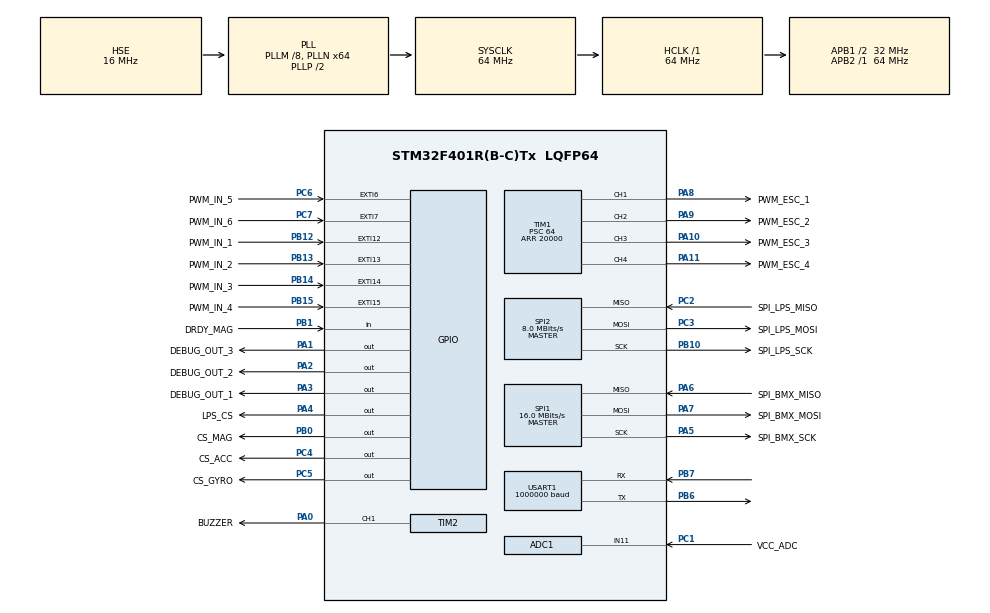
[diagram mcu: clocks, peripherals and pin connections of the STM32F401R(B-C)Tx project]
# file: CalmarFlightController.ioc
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Mcu.Family=STM32F4
PC3.Mode=Full_Duplex_Master
PA6.Mode=Full_Duplex_Master
SH.S_TIM1_CH4.0=TIM1_CH4,PWM Generation4 CH4
RCC.CortexFreq_Value=64000000
SPI1.VirtualType=VM_MASTER
SPI2.VirtualType=VM_MASTER
PB10.Mode=Full_Duplex_Master
ADC1.ContinuousConvMode=DISABLE
USART1.BaudRate=1000000
PB14.GPIO_Label=PWM_IN_3
PC6.GPIO_Label=PWM_IN_5
PA6.GPIO_Label=SPI_BMX_MISO
PB0.GPIO_Label=CS_MAG
TIM1.Pulse-PWM\ Generation1\ CH1=1000
PB13.GPIO_Label=PWM_IN_2
PB13.Signal=GPXTI13
PB15.Signal=GPXTI15
RCC.SYSCLKSource=RCC_SYSCLKSOURCE_PLLCLK
ProjectManager.StackSize=0x400
TIM1.OC1Preload_PWM=ENABLE
TIM1.Prescaler=64
SPI1.CLKPolarity=SPI_POLARITY_LOW
PH0\ -\ OSC_IN.Signal=RCC_OSC_IN
TIM1.Channel-PWM\ Generation4\ CH4=TIM_CHANNEL_4
SPI1.Direction=SPI_DIRECTION_2LINES
RCC.HCLKFreq_Value=64000000
RCC.APB2TimFreq_Value=64000000
PB6.Signal=USART1_TX
Dma.ADC1.0.Direction=DMA_PERIPH_TO_MEMORY
ADC1.Channel-2\#ChannelRegularConversion=ADC_CHANNEL_11
PC7.Signal=GPXTI7
ADC1.InjNumberOfConversion=0
PB6.Mode=Asynchronous
SPI1.CalculateBaudRate=16.0 MBits/s
PC3.Signal=SPI2_MOSI
NVIC.DMA2_Stream0_IRQn=true\:5\:0\:false\:false\:true\:true\:false\:true
FREERTOS.configMINIMAL_STACK_SIZE=128
Dma.ADC1.0.MemDataAlignment=DMA_MDATAALIGN_WORD
RCC.AHBFreq_Value=64000000
SPI2.BaudRatePrescaler=SPI_BAUDRATEPRESCALER_4
NVIC.EXTI15_10_IRQn=true\:5\:0\:false\:false\:true\:true\:true\:true
RCC.HSE_VALUE=16000000
PB12.GPIO_Label=PWM_IN_1
ADC1.Rank-2\#ChannelRegularConversion=1
PC4.GPIO_Label=CS_ACC
TIM1.Channel-PWM\ Generation1\ CH1=TIM_CHANNEL_1
TIM1.OC2Preload_PWM=ENABLE
PB1.GPIO_Label=DRDY_MAG
Dma.ADC1.0.PeriphInc=DMA_PINC_DISABLE
NVIC.TIM2_IRQn=true\:5\:0\:false\:false\:true\:true\:true\:true
PA10.GPIO_Label=PWM_ESC_3
SPI2.CalculateBaudRate=8.0 MBits/s
PB7.Signal=USART1_RX
PA8.Signal=S_TIM1_CH1
TIM2.Channel-PWM\ Generation1\ CH1=TIM_CHANNEL_1
VP_FREERTOS_VS_CMSIS_V1.Mode=CMSIS_V1
VP_TIM1_VS_ClockSourceINT.Mode=Internal
PC7.GPIO_ModeDefaultEXTI=GPIO_MODE_IT_RISING_FALLING
Mcu.Package=LQFP64
TIM2.Prescaler=64
PB1.Signal=GPIO_Input
PA6.Signal=SPI1_MISO
NVIC.TimeBase=TIM3_IRQn
SPI2.Mode=SPI_MODE_MASTER
TIM1.Pulse-PWM\ Generation2\ CH2=1000
PA2.GPIO_Label=DEBUG_OUT_2
NVIC.TimeBaseIP=TIM3
PA10.Signal=S_TIM1_CH3
RCC.APB1TimFreq_Value=64000000
Dma.ADC1.0.FIFOMode=DMA_FIFOMODE_DISABLE
SPI2.Direction=SPI_DIRECTION_2LINES
PC5.Signal=GPIO_Output
TIM1.Period=20000
Dma.Request0=ADC1
SPI1.BaudRatePrescaler=SPI_BAUDRATEPRESCALER_4
PA4.GPIO_Label=LPS_CS
PC2.GPIO_Label=SPI_LPS_MISO
ADC1.EOCSelection=ADC_EOC_SEQ_CONV
PA3.Signal=GPIO_Output
PA5.Mode=Full_Duplex_Master
PB14.GPIO_ModeDefaultEXTI=GPIO_MODE_IT_RISING_FALLING
RCC.PLLSourceVirtual=RCC_PLLSOURCE_HSE
Dma.ADC1.0.Instance=DMA2_Stream0
FREERTOS.Tasks01=defaultTask,-3,128,StartDefaultTask,Default,NULL,Dynamic,NULL,NULL
PA7.Mode=Full_Duplex_Master
PA9.GPIO_Label=PWM_ESC_2
FREERTOS.INCLUDE_vTaskDelayUntil=1
TIM1.OC3Preload_PWM=ENABLE
PH1\ -\ OSC_OUT.Mode=HSE-External-Oscillator
PC2.Signal=SPI2_MISO
PC4.Signal=GPIO_Output
PC6.Signal=GPXTI6
PA11.GPIO_Label=PWM_ESC_4
PC2.Mode=Full_Duplex_Master
SPI1.CLKPhase=SPI_PHASE_1EDGE
TIM1.OC4Preload_PWM=ENABLE
RCC.APB1CLKDivider=RCC_HCLK_DIV2
PB13.GPIO_ModeDefaultEXTI=GPIO_MODE_IT_RISING_FALLING
ADC1.SamplingTime-2\#ChannelRegularConversion=ADC_SAMPLETIME_3CYCLES
PA0-WKUP.GPIO_Label=BUZZER
PA0-WKUP.Signal=S_TIM2_CH1_ETR
TIM1.ClockDivision=TIM_CLOCKDIVISION_DIV1
TIM2.Pulse-PWM\ Generation1\ CH1=1000
TIM1.Pulse-PWM\ Generation3\ CH3=1000
TIM1.AutoReloadPreload=TIM_AUTORELOAD_PRELOAD_ENABLE
Dma.ADC1.0.PeriphDataAlignment=DMA_PDATAALIGN_WORD
PH0\ -\ OSC_IN.Mode=HSE-External-Oscillator
VP_SYS_VS_tim3.Mode=TIM3
PA8.GPIO_Label=PWM_ESC_1
SH.S_TIM1_CH1.0=TIM1_CH1,PWM Generation1 CH1
PC6.GPIO_ModeDefaultEXTI=GPIO_MODE_IT_RISING_FALLING
ProjectManager.TargetToolchain=STM32CubeIDE
PB10.GPIO_Label=SPI_LPS_SCK
Dma.ADC1.0.Mode=DMA_CIRCULAR
Dma.ADC1.0.Priority=DMA_PRIORITY_LOW
PA9.Signal=S_TIM1_CH2
TIM1.Channel-PWM\ Generation2\ CH2=TIM_CHANNEL_2
RCC.LSE_VALUE=32768
PA1.Signal=GPIO_Output
PB10.Signal=SPI2_SCK
PB14.Signal=GPXTI14
PA5.Signal=SPI1_SCK
PB15.GPIO_ModeDefaultEXTI=GPIO_MODE_IT_RISING_FALLING
PH1\ -\ OSC_OUT.Signal=RCC_OSC_OUT
board=custom
RCC.VCOOutputFreq_Value=128000000
NVIC.TIM3_IRQn=true\:0\:0\:false\:false\:true\:false\:false\:true
FREERTOS.INCLUDE_eTaskGetState=1
TIM1.TIM_MasterOutputTrigger=TIM_TRGO_UPDATE
RCC.APB2Freq_Value=64000000
SH.ADCx_IN11.0=ADC1_IN11,IN11
PB15.GPIO_Label=PWM_IN_4
SH.S_TIM1_CH2.0=TIM1_CH2,PWM Generation2 CH2
VP_TIM2_VS_ClockSourceINT.Mode=Internal
SPI1.Mode=SPI_MODE_MASTER
PA1.GPIO_Label=DEBUG_OUT_3
PC1.GPIO_Label=VCC_ADC
ADC1.DMAContinuousRequests=ENABLE
TIM2.Period=2000
ADC1.NbrOfConversion=1
Mcu.Name=STM32F401R(B-C)Tx
PA2.Signal=GPIO_Output
PC7.GPIO_Label=PWM_IN_6
RCC.48MHZClocksFreq_Value=32000000
PA4.Signal=GPIO_Output
RCC.SYSCLKFreq_VALUE=64000000
PA7.GPIO_Label=SPI_BMX_MOSI
ADC1.master=1
PA5.GPIO_Label=SPI_BMX_SCK
PC5.GPIO_Label=CS_GYRO
USART1.VirtualMode=VM_ASYNC
PA11.Signal=S_TIM1_CH4
PB7.Mode=Asynchronous
SH.S_TIM2_CH1_ETR.0=TIM2_CH1,PWM Generation1 CH1
NVIC.EXTI9_5_IRQn=true\:5\:0\:false\:false\:true\:true\:true\:true
Dma.ADC1.0.MemInc=DMA_MINC_ENABLE
ProjectManager.HeapSize=0x200
SH.S_TIM1_CH3.0=TIM1_CH3,PWM Generation3 CH3
TIM1.Pulse-PWM\ Generation4\ CH4=1000
PB12.GPIO_ModeDefaultEXTI=GPIO_MODE_IT_RISING_FALLING
RCC.HSI_VALUE=16000000
NVIC.PriorityGroup=NVIC_PRIORITYGROUP_4
ADC1.NbrOfConversionFlag=1
RCC.PLLM=8
RCC.PLLN=64
TIM2.AutoReloadPreload=TIM_AUTORELOAD_PRELOAD_ENABLE
PC3.GPIO_Label=SPI_LPS_MOSI
TIM1.Channel-PWM\ Generation3\ CH3=TIM_CHANNEL_3
RCC.APB1Freq_Value=32000000
PB0.Signal=GPIO_Output
ADC1.ClockPrescaler=ADC_CLOCK_SYNC_PCLK_DIV2
PC1.Signal=ADCx_IN11
PB12.Signal=GPXTI12
PA3.GPIO_Label=DEBUG_OUT_1
PA7.Signal=SPI1_MOSI

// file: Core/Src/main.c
/* USER CODE BEGIN Header */
/**
  ******************************************************************************
  * @file           : main.c
  * @brief          : Main program body
  ******************************************************************************
  * @attention
  *
  * <h2><center>&copy; Copyright (c) 2020 STMicroelectronics.
  * All rights reserved.</center></h2>
  *
  * This software component is licensed by ST under BSD 3-Clause license,
  * the "License"; You may not use this file except in compliance with the
  * License. You may obtain a copy of the License at:
  *                        opensource.org/licenses/BSD-3-Clause
  *
  ******************************************************************************
  */
/* USER CODE END Header */
#include "main.h"
#include "cmsis_os.h"

/* USER CODE BEGIN Includes */
#include "app/deviceManager/deviceManager.h"
/* USER CODE END Includes */

ADC_HandleTypeDef hadc1;
DMA_HandleTypeDef hdma_adc1;

SPI_HandleTypeDef hspi1;
SPI_HandleTypeDef hspi2;

TIM_HandleTypeDef htim1;
TIM_HandleTypeDef htim2;

UART_HandleTypeDef huart1;

osThreadId defaultTaskHandle;

void SystemClock_Config(void);
static void MX_GPIO_Init(void);
static void MX_DMA_Init(void);
static void MX_ADC1_Init(void);
static void MX_SPI1_Init(void);
static void MX_SPI2_Init(void);
static void MX_TIM1_Init(void);
static void MX_TIM2_Init(void);
static void MX_USART1_UART_Init(void);
void StartDefaultTask(void const * argument);

int main(void)
{

  /* MCU Configuration--------------------------------------------------------*/

  /* Reset of all peripherals, Initializes the Flash interface and the Systick. */
  HAL_Init();

  /* USER CODE BEGIN Init */
  HAL_Delay(1000);
  /* USER CODE END Init */

  /* Configure the system clock */
  SystemClock_Config();

  /* Initialize all configured peripherals */
  MX_GPIO_Init();
  MX_DMA_Init();
  MX_ADC1_Init();
  MX_SPI1_Init();
  MX_SPI2_Init();
  MX_TIM1_Init();
  MX_TIM2_Init();
  MX_USART1_UART_Init();
  /* USER CODE BEGIN 2 */
  DeviceManagerInit(&hadc1,&hspi1,&hspi2,&htim2,&huart1,&htim1);
  /* USER CODE END 2 */

  /* Create the thread(s) */
  /* definition and creation of defaultTask */
  osThreadDef(defaultTask, StartDefaultTask, osPriorityIdle, 0, 128);
  defaultTaskHandle = osThreadCreate(osThread(defaultTask), NULL);

  /* Start scheduler */
  osKernelStart();

  /* We should never get here as control is now taken by the scheduler */
  /* Infinite loop */
  while (1)
  {

  }
}

void SystemClock_Config(void)
{
  RCC_OscInitTypeDef RCC_OscInitStruct = {0};
  RCC_ClkInitTypeDef RCC_ClkInitStruct = {0};

  /** Configure the main internal regulator output voltage
  */
  __HAL_RCC_PWR_CLK_ENABLE();
  __HAL_PWR_VOLTAGESCALING_CONFIG(PWR_REGULATOR_VOLTAGE_SCALE2);
  /** Initializes the RCC Oscillators according to the specified parameters
  * in the RCC_OscInitTypeDef structure.
  */
  RCC_OscInitStruct.OscillatorType = RCC_OSCILLATORTYPE_HSE;
  RCC_OscInitStruct.HSEState = RCC_HSE_ON;
  RCC_OscInitStruct.PLL.PLLState = RCC_PLL_ON;
  RCC_OscInitStruct.PLL.PLLSource = RCC_PLLSOURCE_HSE;
  RCC_OscInitStruct.PLL.PLLM = 8;
  RCC_OscInitStruct.PLL.PLLN = 64;
  RCC_OscInitStruct.PLL.PLLP = RCC_PLLP_DIV2;
  RCC_OscInitStruct.PLL.PLLQ = 4;
  if (HAL_RCC_OscConfig(&RCC_OscInitStruct) != HAL_OK)
  {
    Error_Handler();
  }
  /** Initializes the CPU, AHB and APB buses clocks
  */
  RCC_ClkInitStruct.ClockType = RCC_CLOCKTYPE_HCLK|RCC_CLOCKTYPE_SYSCLK
                              |RCC_CLOCKTYPE_PCLK1|RCC_CLOCKTYPE_PCLK2;
  RCC_ClkInitStruct.SYSCLKSource = RCC_SYSCLKSOURCE_PLLCLK;
  RCC_ClkInitStruct.AHBCLKDivider = RCC_SYSCLK_DIV1;
  RCC_ClkInitStruct.APB1CLKDivider = RCC_HCLK_DIV2;
  RCC_ClkInitStruct.APB2CLKDivider = RCC_HCLK_DIV1;

  if (HAL_RCC_ClockConfig(&RCC_ClkInitStruct, FLASH_LATENCY_2) != HAL_OK)
  {
    Error_Handler();
  }
}

static void MX_ADC1_Init(void)
{

  ADC_ChannelConfTypeDef sConfig = {0};

  /** Configure the global features of the ADC (Clock, Resolution, Data Alignment and number of conversion)
  */
  hadc1.Instance = ADC1;
  hadc1.Init.ClockPrescaler = ADC_CLOCK_SYNC_PCLK_DIV2;
  hadc1.Init.Resolution = ADC_RESOLUTION_12B;
  hadc1.Init.ScanConvMode = DISABLE;
  hadc1.Init.ContinuousConvMode = DISABLE;
  hadc1.Init.DiscontinuousConvMode = DISABLE;
  hadc1.Init.ExternalTrigConvEdge = ADC_EXTERNALTRIGCONVEDGE_NONE;
  hadc1.Init.ExternalTrigConv = ADC_SOFTWARE_START;
  hadc1.Init.DataAlign = ADC_DATAALIGN_RIGHT;
  hadc1.Init.NbrOfConversion = 1;
  hadc1.Init.DMAContinuousRequests = ENABLE;
  hadc1.Init.EOCSelection = ADC_EOC_SEQ_CONV;
  if (HAL_ADC_Init(&hadc1) != HAL_OK)
  {
    Error_Handler();
  }
  /** Configure for the selected ADC regular channel its corresponding rank in the sequencer and its sample time.
  */
  sConfig.Channel = ADC_CHANNEL_11;
  sConfig.Rank = 1;
  sConfig.SamplingTime = ADC_SAMPLETIME_3CYCLES;
  if (HAL_ADC_ConfigChannel(&hadc1, &sConfig) != HAL_OK)
  {
    Error_Handler();
  }

}

static void MX_SPI1_Init(void)
{

  /* SPI1 parameter configuration*/
  hspi1.Instance = SPI1;
  hspi1.Init.Mode = SPI_MODE_MASTER;
  hspi1.Init.Direction = SPI_DIRECTION_2LINES;
  hspi1.Init.DataSize = SPI_DATASIZE_8BIT;
  hspi1.Init.CLKPolarity = SPI_POLARITY_LOW;
  hspi1.Init.CLKPhase = SPI_PHASE_1EDGE;
  hspi1.Init.NSS = SPI_NSS_SOFT;
  hspi1.Init.BaudRatePrescaler = SPI_BAUDRATEPRESCALER_4;
  hspi1.Init.FirstBit = SPI_FIRSTBIT_MSB;
  hspi1.Init.TIMode = SPI_TIMODE_DISABLE;
  hspi1.Init.CRCCalculation = SPI_CRCCALCULATION_DISABLE;
  hspi1.Init.CRCPolynomial = 10;
  if (HAL_SPI_Init(&hspi1) != HAL_OK)
  {
    Error_Handler();
  }

}

static void MX_SPI2_Init(void)
{

  /* SPI2 parameter configuration*/
  hspi2.Instance = SPI2;
  hspi2.Init.Mode = SPI_MODE_MASTER;
  hspi2.Init.Direction = SPI_DIRECTION_2LINES;
  hspi2.Init.DataSize = SPI_DATASIZE_8BIT;
  hspi2.Init.CLKPolarity = SPI_POLARITY_LOW;
  hspi2.Init.CLKPhase = SPI_PHASE_1EDGE;
  hspi2.Init.NSS = SPI_NSS_SOFT;
  hspi2.Init.BaudRatePrescaler = SPI_BAUDRATEPRESCALER_4;
  hspi2.Init.FirstBit = SPI_FIRSTBIT_MSB;
  hspi2.Init.TIMode = SPI_TIMODE_DISABLE;
  hspi2.Init.CRCCalculation = SPI_CRCCALCULATION_DISABLE;
  hspi2.Init.CRCPolynomial = 10;
  if (HAL_SPI_Init(&hspi2) != HAL_OK)
  {
    Error_Handler();
  }

}

static void MX_TIM1_Init(void)
{

  TIM_ClockConfigTypeDef sClockSourceConfig = {0};
  TIM_MasterConfigTypeDef sMasterConfig = {0};
  TIM_OC_InitTypeDef sConfigOC = {0};
  TIM_BreakDeadTimeConfigTypeDef sBreakDeadTimeConfig = {0};

  htim1.Instance = TIM1;
  htim1.Init.Prescaler = 64;
  htim1.Init.CounterMode = TIM_COUNTERMODE_UP;
  htim1.Init.Period = 20000;
  htim1.Init.ClockDivision = TIM_CLOCKDIVISION_DIV1;
  htim1.Init.RepetitionCounter = 0;
  htim1.Init.AutoReloadPreload = TIM_AUTORELOAD_PRELOAD_ENABLE;
  if (HAL_TIM_Base_Init(&htim1) != HAL_OK)
  {
    Error_Handler();
  }
  sClockSourceConfig.ClockSource = TIM_CLOCKSOURCE_INTERNAL;
  if (HAL_TIM_ConfigClockSource(&htim1, &sClockSourceConfig) != HAL_OK)
  {
    Error_Handler();
  }
  if (HAL_TIM_PWM_Init(&htim1) != HAL_OK)
  {
    Error_Handler();
  }
  sMasterConfig.MasterOutputTrigger = TIM_TRGO_UPDATE;
  sMasterConfig.MasterSlaveMode = TIM_MASTERSLAVEMODE_DISABLE;
  if (HAL_TIMEx_MasterConfigSynchronization(&htim1, &sMasterConfig) != HAL_OK)
  {
    Error_Handler();
  }
  sConfigOC.OCMode = TIM_OCMODE_PWM1;
  sConfigOC.Pulse = 1000;
  sConfigOC.OCPolarity = TIM_OCPOLARITY_HIGH;
  sConfigOC.OCNPolarity = TIM_OCNPOLARITY_HIGH;
  sConfigOC.OCFastMode = TIM_OCFAST_DISABLE;
  sConfigOC.OCIdleState = TIM_OCIDLESTATE_RESET;
  sConfigOC.OCNIdleState = TIM_OCNIDLESTATE_RESET;
  if (HAL_TIM_PWM_ConfigChannel(&htim1, &sConfigOC, TIM_CHANNEL_1) != HAL_OK)
  {
    Error_Handler();
  }
  if (HAL_TIM_PWM_ConfigChannel(&htim1, &sConfigOC, TIM_CHANNEL_2) != HAL_OK)
  {
    Error_Handler();
  }
  if (HAL_TIM_PWM_ConfigChannel(&htim1, &sConfigOC, TIM_CHANNEL_3) != HAL_OK)
  {
    Error_Handler();
  }
  if (HAL_TIM_PWM_ConfigChannel(&htim1, &sConfigOC, TIM_CHANNEL_4) != HAL_OK)
  {
    Error_Handler();
  }
  sBreakDeadTimeConfig.OffStateRunMode = TIM_OSSR_DISABLE;
  sBreakDeadTimeConfig.OffStateIDLEMode = TIM_OSSI_DISABLE;
  sBreakDeadTimeConfig.LockLevel = TIM_LOCKLEVEL_OFF;
  sBreakDeadTimeConfig.DeadTime = 0;
  sBreakDeadTimeConfig.BreakState = TIM_BREAK_DISABLE;
  sBreakDeadTimeConfig.BreakPolarity = TIM_BREAKPOLARITY_HIGH;
  sBreakDeadTimeConfig.AutomaticOutput = TIM_AUTOMATICOUTPUT_DISABLE;
  if (HAL_TIMEx_ConfigBreakDeadTime(&htim1, &sBreakDeadTimeConfig) != HAL_OK)
  {
    Error_Handler();
  }
  HAL_TIM_MspPostInit(&htim1);

}

static void MX_TIM2_Init(void)
{

  TIM_ClockConfigTypeDef sClockSourceConfig = {0};
  TIM_MasterConfigTypeDef sMasterConfig = {0};
  TIM_OC_InitTypeDef sConfigOC = {0};

  htim2.Instance = TIM2;
  htim2.Init.Prescaler = 64;
  htim2.Init.CounterMode = TIM_COUNTERMODE_UP;
  htim2.Init.Period = 2000;
  htim2.Init.ClockDivision = TIM_CLOCKDIVISION_DIV1;
  htim2.Init.AutoReloadPreload = TIM_AUTORELOAD_PRELOAD_ENABLE;
  if (HAL_TIM_Base_Init(&htim2) != HAL_OK)
  {
    Error_Handler();
  }
  sClockSourceConfig.ClockSource = TIM_CLOCKSOURCE_INTERNAL;
  if (HAL_TIM_ConfigClockSource(&htim2, &sClockSourceConfig) != HAL_OK)
  {
    Error_Handler();
  }
  if (HAL_TIM_PWM_Init(&htim2) != HAL_OK)
  {
    Error_Handler();
  }
  sMasterConfig.MasterOutputTrigger = TIM_TRGO_RESET;
  sMasterConfig.MasterSlaveMode = TIM_MASTERSLAVEMODE_DISABLE;
  if (HAL_TIMEx_MasterConfigSynchronization(&htim2, &sMasterConfig) != HAL_OK)
  {
    Error_Handler();
  }
  sConfigOC.OCMode = TIM_OCMODE_PWM1;
  sConfigOC.Pulse = 1000;
  sConfigOC.OCPolarity = TIM_OCPOLARITY_HIGH;
  sConfigOC.OCFastMode = TIM_OCFAST_DISABLE;
  if (HAL_TIM_PWM_ConfigChannel(&htim2, &sConfigOC, TIM_CHANNEL_1) != HAL_OK)
  {
    Error_Handler();
  }
  HAL_TIM_MspPostInit(&htim2);

}

static void MX_USART1_UART_Init(void)
{

  huart1.Instance = USART1;
  huart1.Init.BaudRate = 1000000;
  huart1.Init.WordLength = UART_WORDLENGTH_8B;
  huart1.Init.StopBits = UART_STOPBITS_1;
  huart1.Init.Parity = UART_PARITY_NONE;
  huart1.Init.Mode = UART_MODE_TX_RX;
  huart1.Init.HwFlowCtl = UART_HWCONTROL_NONE;
  huart1.Init.OverSampling = UART_OVERSAMPLING_16;
  if (HAL_UART_Init(&huart1) != HAL_OK)
  {
    Error_Handler();
  }

}

static void MX_DMA_Init(void)
{

  /* DMA controller clock enable */
  __HAL_RCC_DMA2_CLK_ENABLE();

  /* DMA interrupt init */
  /* DMA2_Stream0_IRQn interrupt configuration */
  HAL_NVIC_SetPriority(DMA2_Stream0_IRQn, 5, 0);
  HAL_NVIC_EnableIRQ(DMA2_Stream0_IRQn);

}

static void MX_GPIO_Init(void)
{
  GPIO_InitTypeDef GPIO_InitStruct = {0};

  /* GPIO Ports Clock Enable */
  __HAL_RCC_GPIOH_CLK_ENABLE();
  __HAL_RCC_GPIOC_CLK_ENABLE();
  __HAL_RCC_GPIOA_CLK_ENABLE();
  __HAL_RCC_GPIOB_CLK_ENABLE();

  /*Configure GPIO pin Output Level */
  HAL_GPIO_WritePin(GPIOA, DEBUG_OUT_3_Pin|DEBUG_OUT_2_Pin|DEBUG_OUT_1_Pin|LPS_CS_Pin, GPIO_PIN_RESET);

  /*Configure GPIO pin Output Level */
  HAL_GPIO_WritePin(GPIOC, CS_ACC_Pin|CS_GYRO_Pin, GPIO_PIN_RESET);

  /*Configure GPIO pin Output Level */
  HAL_GPIO_WritePin(CS_MAG_GPIO_Port, CS_MAG_Pin, GPIO_PIN_RESET);

  /*Configure GPIO pins : DEBUG_OUT_3_Pin DEBUG_OUT_2_Pin DEBUG_OUT_1_Pin LPS_CS_Pin */
  GPIO_InitStruct.Pin = DEBUG_OUT_3_Pin|DEBUG_OUT_2_Pin|DEBUG_OUT_1_Pin|LPS_CS_Pin;
  GPIO_InitStruct.Mode = GPIO_MODE_OUTPUT_PP;
  GPIO_InitStruct.Pull = GPIO_NOPULL;
  GPIO_InitStruct.Speed = GPIO_SPEED_FREQ_LOW;
  HAL_GPIO_Init(GPIOA, &GPIO_InitStruct);

  /*Configure GPIO pins : CS_ACC_Pin CS_GYRO_Pin */
  GPIO_InitStruct.Pin = CS_ACC_Pin|CS_GYRO_Pin;
  GPIO_InitStruct.Mode = GPIO_MODE_OUTPUT_PP;
  GPIO_InitStruct.Pull = GPIO_NOPULL;
  GPIO_InitStruct.Speed = GPIO_SPEED_FREQ_LOW;
  HAL_GPIO_Init(GPIOC, &GPIO_InitStruct);

  /*Configure GPIO pin : CS_MAG_Pin */
  GPIO_InitStruct.Pin = CS_MAG_Pin;
  GPIO_InitStruct.Mode = GPIO_MODE_OUTPUT_PP;
  GPIO_InitStruct.Pull = GPIO_NOPULL;
  GPIO_InitStruct.Speed = GPIO_SPEED_FREQ_LOW;
  HAL_GPIO_Init(CS_MAG_GPIO_Port, &GPIO_InitStruct);

  /*Configure GPIO pin : DRDY_MAG_Pin */
  GPIO_InitStruct.Pin = DRDY_MAG_Pin;
  GPIO_InitStruct.Mode = GPIO_MODE_INPUT;
  GPIO_InitStruct.Pull = GPIO_NOPULL;
  HAL_GPIO_Init(DRDY_MAG_GPIO_Port, &GPIO_InitStruct);

  /*Configure GPIO pins : PWM_IN_1_Pin PWM_IN_2_Pin PWM_IN_3_Pin PWM_IN_4_Pin */
  GPIO_InitStruct.Pin = PWM_IN_1_Pin|PWM_IN_2_Pin|PWM_IN_3_Pin|PWM_IN_4_Pin;
  GPIO_InitStruct.Mode = GPIO_MODE_IT_RISING_FALLING;
  GPIO_InitStruct.Pull = GPIO_NOPULL;
  HAL_GPIO_Init(GPIOB, &GPIO_InitStruct);

  /*Configure GPIO pins : PWM_IN_5_Pin PWM_IN_6_Pin */
  GPIO_InitStruct.Pin = PWM_IN_5_Pin|PWM_IN_6_Pin;
  GPIO_InitStruct.Mode = GPIO_MODE_IT_RISING_FALLING;
  GPIO_InitStruct.Pull = GPIO_NOPULL;
  HAL_GPIO_Init(GPIOC, &GPIO_InitStruct);

  /* EXTI interrupt init*/
  HAL_NVIC_SetPriority(EXTI9_5_IRQn, 5, 0);
  HAL_NVIC_EnableIRQ(EXTI9_5_IRQn);

  HAL_NVIC_SetPriority(EXTI15_10_IRQn, 5, 0);
  HAL_NVIC_EnableIRQ(EXTI15_10_IRQn);

}

void StartDefaultTask(void const * argument)
{
  /* USER CODE BEGIN 5 */
  /* Infinite loop */

  for(;;)
  {
      osDelay(2000);
  }
  /* USER CODE END 5 */
}

 /**
  * @brief  Period elapsed callback in non blocking mode
  * @note   This function is called  when TIM3 interrupt took place, inside
  * HAL_TIM_IRQHandler(). It makes a direct call to HAL_IncTick() to increment
  * a global variable "uwTick" used as application time base.
  * @param  htim : TIM handle
  * @retval None
  */
void HAL_TIM_PeriodElapsedCallback(TIM_HandleTypeDef *htim)
{
  if (htim->Instance == TIM3) {
    HAL_IncTick();
  }
}

void Error_Handler(void)
{
}

/************************ (C) COPYRIGHT STMicroelectronics *****END OF FILE****/
